# STM32F101_iown register map
Vendor: iown-homecontrol; Series: CM3; File version: 1.3
CPU: CM3 r1p1, little endian, no MPU, no FPU, VTOR, 4 interrupt priority bits
Registers are 32-bit, read-write, reset 0x0 unless marked. A register's access mark holds for its fields unless they carry their own. Offsets are from the block's base; [hi:lo] are bit positions; {n}, {i} and the like mark numbered series; 'fields as' and 'values as' point back to an identical list; <NAME> marks a mode.

## CRC — CRC calculation unit
Base 0x40023000
0x00 DR reset 0xFFFFFFFF — Data register
  [31:0] DR — Data Register
0x04 IDR — Independent Data register
  [7:0] IDR
0x08 CR wo — Control register
  [0] RESET — Reset bit
    on write: 1=Resets the CRC calculation unit and sets the data register to 0xFFFF FFFF

## FLASH
Base 0x40022000
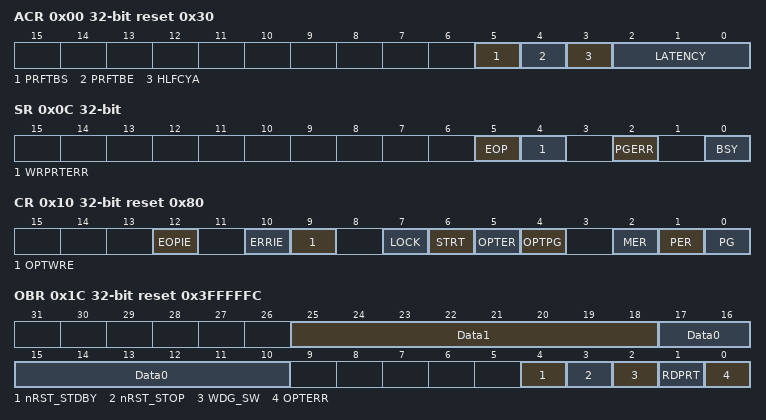
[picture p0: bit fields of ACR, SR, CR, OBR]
0x00 ACR reset 0x30 — Flash access control register
  [5] PRFTBS ro — Prefetch buffer status
  [4] PRFTBE — Prefetch buffer enable
  [3] HLFCYA — Flash half cycle access enable
  [2:0] LATENCY
    0=WS0 (Zero wait state, if 0 < SYSCLK< 24 MHz); 1=WS1 (One wait state, if 24 MHz < SYSCLK < 48 MHz); 2=WS2 (Two wait states, if 48 MHz < SYSCLK < 72 MHz)
0x04 KEYR wo — Flash key register
  [31:0] KEY — FPEC key
0x08 OPTKEYR wo — Flash option key register
  [31:0] OPTKEY — Option byte key
0x0C SR — Status register
  [5] EOP — End of operation
  [4] WRPRTERR — Write protection error
  [2] PGERR — Programming error
  [0] BSY ro — Busy
0x10 CR reset 0x80 — Control register
  [12] EOPIE — End of operation interrupt enable
  [10] ERRIE — Error interrupt enable
  [9] OPTWRE — Option bytes write enable
  [7] LOCK
  [6] STRT — Start
  [5] OPTER — Option byte erase
  [4] OPTPG — Option byte programming
  [2] MER — Mass Erase
  [1] PER — Page Erase
  [0] PG — Programming
0x14 AR wo — Flash address register
  [31:0] FAR — Flash Address
0x1C OBR ro reset 0x3FFFFFC — Option byte register
  [25:18] Data1
  [17:10] Data0
  [4] nRST_STDBY
  [3] nRST_STOP
  [2] WDG_SW
  [1] RDPRT — Read protection
  [0] OPTERR — Option byte error
0x20 WRPR ro reset 0xFFFFFFFF — Write protection register
  [31:0] WRP — Write protect

## BKP — Backup registers
Base 0x40006C00
0x00 DR{i} (i=1..10; step 0x4) — Backup data register (BKP_DR)
  [15:0] D — Backup data
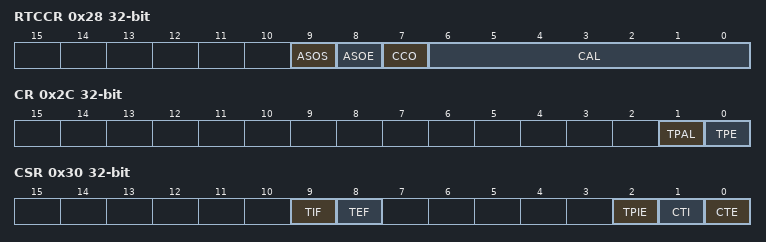
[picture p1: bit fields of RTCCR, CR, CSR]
0x28 RTCCR — RTC clock calibration register (BKP_RTCCR)
  [9] ASOS — Alarm or second output selection
    0=Alarm (RTC Alarm pulse output selected); 1=Second (RTC Second pulse output selected)
  [8] ASOE — Alarm or second output enable
    0=Disabled; 1=Enabled (Setting this bit outputs either the RTC Alarm pulse signal or the Second pulse signal on the TAMPER pin depending on the ASOS bit)
  [7] CCO — Calibration Clock Output
  [6:0] CAL range 0..121 — Calibration value
0x2C CR — Backup control register (BKP_CR)
  [1] TPAL — Tamper pin active level
    0=High (A high level on the TAMPER pin resets all data backup registers (if TPE bit is set)); 1=Low (A low level on the TAMPER pin resets all data backup registers (if TPE bit is set))
  [0] TPE — Tamper pin enable
    0=General (The TAMPER pin is free for general purpose I/O); 1=Alternate (Tamper alternate I/O function is activated)
0x30 CSR — BKP_CSR control/status register (BKP_CSR)
  [9] TIF ro — Tamper Interrupt Flag
  [8] TEF ro — Tamper Event Flag
  [2] TPIE — Tamper Pin interrupt enable
    0=Disabled (Tamper interrupt disabled); 1=Enabled (Tamper interrupt enabled (the TPE bit must also be set in the BKP_CR register)
  [1] CTI wo — Clear Tamper Interrupt
    on write: 1=Clear the Tamper interrupt and the TIF Tamper interrupt flag
  [0] CTE wo — Clear Tamper event
    on write: 1=Reset the TEF Tamper event flag (and the Tamper detector)
{0x10+4i} BKP_DR{i} (i=11..42) — Backup data register (BKP_DR)
  [15:0] D — Backup data

## OTG_FS_HOST — USB on the go full speed
Base 0x50000400
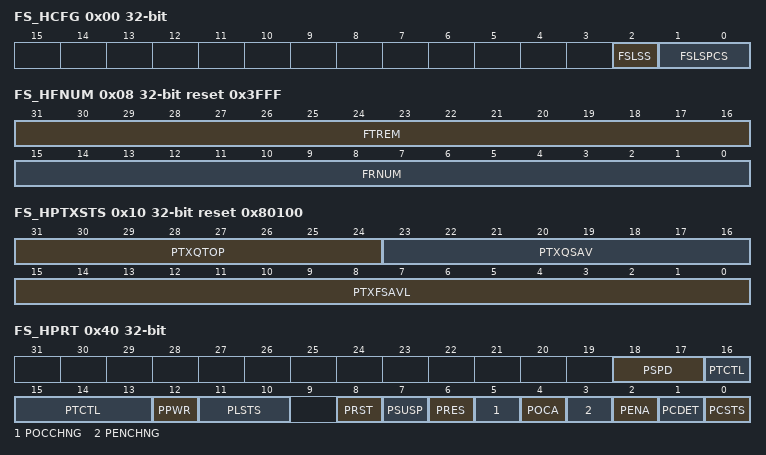
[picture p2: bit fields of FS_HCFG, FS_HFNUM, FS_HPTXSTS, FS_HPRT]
0x00 FS_HCFG — OTG_FS host configuration register (OTG_FS_HCFG)
  [2] FSLSS ro — FS- and LS-only support
  [1:0] FSLSPCS — FS/LS PHY clock select
0x04 HFIR reset 0xEA60 — OTG_FS Host frame interval register
  [15:0] FRIVL — Frame interval
0x08 FS_HFNUM ro reset 0x3FFF — OTG_FS host frame number/frame time remaining register (OTG_FS_HFNUM)
  [31:16] FTREM — Frame time remaining
  [15:0] FRNUM — Frame number
0x10 FS_HPTXSTS reset 0x80100 — OTG_FS_Host periodic transmit FIFO/queue status register (OTG_FS_HPTXSTS)
  [31:24] PTXQTOP ro — Top of the periodic transmit request queue
  [23:16] PTXQSAV ro — Periodic transmit request queue space available
  [15:0] PTXFSAVL — Periodic transmit data FIFO space available
0x14 HAINT ro — OTG_FS Host all channels interrupt register
  [15:0] HAINT — Channel interrupts
0x18 HAINTMSK — OTG_FS host all channels interrupt mask register
  [15:0] HAINTM — Channel interrupt mask
0x40 FS_HPRT — OTG_FS host port control and status register (OTG_FS_HPRT)
  [18:17] PSPD ro — Port speed
  [16:13] PTCTL — Port test control
  [12] PPWR — Port power
  [11:10] PLSTS ro — Port line status
  [8] PRST — Port reset
  [7] PSUSP — Port suspend
  [6] PRES — Port resume
  [5] POCCHNG — Port overcurrent change
  [4] POCA ro — Port overcurrent active
  [3] PENCHNG — Port enable/disable change
  [2] PENA — Port enable
  [1] PCDET — Port connect detected
  [0] PCSTS ro — Port connect status
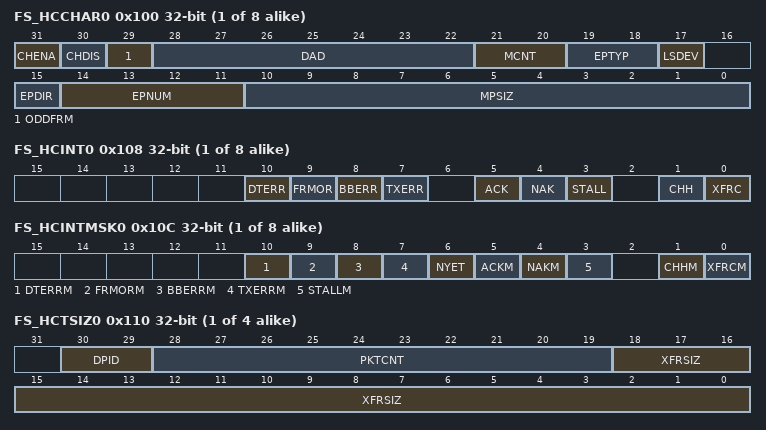
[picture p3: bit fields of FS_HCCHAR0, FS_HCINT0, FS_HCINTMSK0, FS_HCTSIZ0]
{0x100+0x20*i} FS_HCCHAR{i} (i=0..7) — OTG_FS host channel-{i} characteristics register (OTG_FS_HCCHAR{i})
  [31] CHENA — Channel enable
  [30] CHDIS — Channel disable
  [29] ODDFRM — Odd frame
  [28:22] DAD — Device address
  [21:20] MCNT — Multicount
  [19:18] EPTYP — Endpoint type
  [17] LSDEV — Low-speed device
  [15] EPDIR — Endpoint direction
  [14:11] EPNUM — Endpoint number
  [10:0] MPSIZ — Maximum packet size
{0x108+0x20*i} FS_HCINT{i} (i=0..7) — OTG_FS host channel-{i} interrupt register (OTG_FS_HCINT{i})
  [10] DTERR — Data toggle error
  [9] FRMOR — Frame overrun
  [8] BBERR — Babble error
  [7] TXERR — Transaction error
  [5] ACK — ACK response received/transmitted interrupt
  [4] NAK — NAK response received interrupt
  [3] STALL — STALL response received interrupt
  [1] CHH — Channel halted
  [0] XFRC — Transfer completed
{0x10C+0x20*i} FS_HCINTMSK{i} (i=0..7) — OTG_FS host channel-{i} mask register (OTG_FS_HCINTMSK{i})
  [10] DTERRM — Data toggle error mask
  [9] FRMORM — Frame overrun mask
  [8] BBERRM — Babble error mask
  [7] TXERRM — Transaction error mask
  [6] NYET — response received interrupt mask
  [5] ACKM — ACK response received/transmitted interrupt mask
  [4] NAKM — NAK response received interrupt mask
  [3] STALLM — STALL response received interrupt mask
  [1] CHHM — Channel halted mask
  [0] XFRCM — Transfer completed mask
{0x110+0x20*i} FS_HCTSIZ{i} (i=0..3) — OTG_FS host channel-{i} transfer size register
  [30:29] DPID — Data PID
  [28:19] PKTCNT — Packet count
  [18:0] XFRSIZ — Transfer size
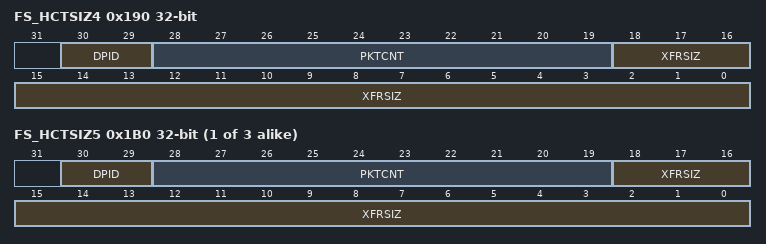
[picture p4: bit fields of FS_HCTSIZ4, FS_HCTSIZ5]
0x190 FS_HCTSIZ4 — OTG_FS host channel-x transfer size register
  fields as FS_HCTSIZ0
{0x110+0x20*i} FS_HCTSIZ{i} (i=5..7) — OTG_FS host channel-{i} transfer size register
  fields as FS_HCTSIZ0
